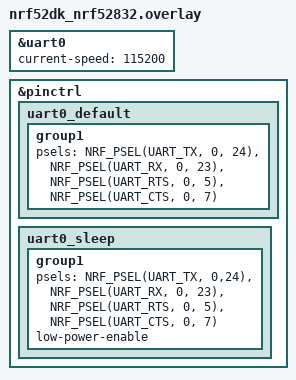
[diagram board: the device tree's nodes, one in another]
&uart0 {
	status = "okay";
	current-speed = < 115200 >;
};

&pinctrl {
    uart0_default: uart0_default {
        group1 {
            psels = <NRF_PSEL(UART_TX, 0, 24)>,
                <NRF_PSEL(UART_RX, 0, 23)>,
                <NRF_PSEL(UART_RTS, 0, 5)>,
                <NRF_PSEL(UART_CTS, 0, 7)>;
        };
    };

    uart0_sleep: uart0_sleep {
        group1 {
            psels = <NRF_PSEL(UART_TX, 0,24)>,
                <NRF_PSEL(UART_RX, 0, 23)>,
                <NRF_PSEL(UART_RTS, 0, 5)>,
                <NRF_PSEL(UART_CTS, 0, 7)>;
            low-power-enable;
        };
    };
};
